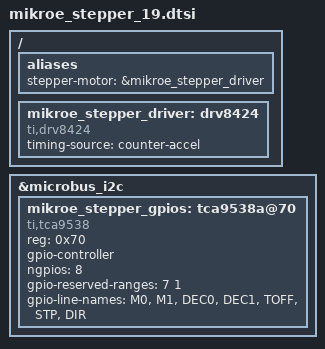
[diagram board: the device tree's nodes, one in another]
/*
 * Copyright (c) 2025 Navimatix GmbH
 * SPDX-License-Identifier: Apache-2.0
 */

/*
 * Aliases for the devices used in the demo, this allows them
 * to be used without knowing the exact hardware configuration.
 */
/ {
	aliases {
		stepper-motor = &mikroe_stepper_driver;
	};

	/* Configuration of the stepper motor driver, a DRV8424. */
	mikroe_stepper_driver: drv8424 {
		compatible = "ti,drv8424";
		status = "okay";

		#address-cells = <1>;
		#size-cells = <0>;
		#stepper-motor-cells = <0>;

		/*
		 * Timing source to generate the step signal. This one uses
		 * a counter to generate the signal and features acceleration.
		 */
		timing-source = "counter-accel";
	};
};

&microbus_i2c {
	status = "okay";

	/* Configuration of the IO expander for driver setups, a TCA9538A. */
	mikroe_stepper_gpios: tca9538a@70 {
		compatible = "ti,tca9538";
		status = "okay";

		reg = <0x70>;

		gpio-controller;
		#gpio-cells = <2>;

		ngpios = <8>;

		gpio-reserved-ranges = <7 1>;
		gpio-line-names = "M0",		/* S0 */
				  "M1",		/* S1 */
				  "DEC0",	/* S2 */
				  "DEC1",	/* S3 */
				  "TOFF",	/* S4 */
				  "STP",	/* S5 */
				  "DIR";	/* S6 */
	};
};
